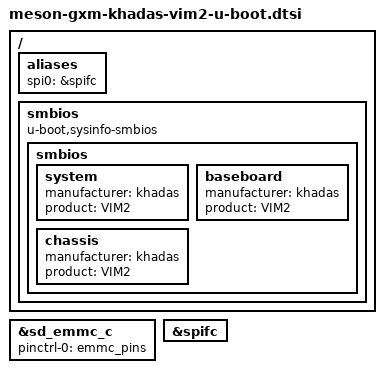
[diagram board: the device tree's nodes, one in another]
// SPDX-License-Identifier: (GPL-2.0+ OR MIT)
/*
 * Copyright (c) 2019 BayLibre, SAS.
 * Author: Neil Armstrong <narmstrong@baylibre.com>
 */

#include "meson-gxl-u-boot.dtsi"

/ {
	aliases {
		spi0 = &spifc;
	};

	smbios {
		compatible = "u-boot,sysinfo-smbios";

		smbios {
			system {
				manufacturer = "khadas";
				product = "VIM2";
			};

			baseboard {
				manufacturer = "khadas";
				product = "VIM2";
			};

			chassis {
				manufacturer = "khadas";
				product = "VIM2";
			};
		};
	};
};

&sd_emmc_c {
	status = "okay";
	pinctrl-0 = <&emmc_pins>;
};

&spifc {
	status = "okay";
};
